# mb9bf566k register map
Vendor: Cypress; Series: mb9bf560l; File version: 1.2
CPU: CM4 r0p1, little endian, MPU, FPU, 4 interrupt priority bits
Registers are 8-bit, read-write, reset 0x0 unless marked. A register's access mark holds for its fields unless they carry their own. Offsets are from the block's base; [hi:lo] are bit positions; {n}, {i} and the like mark numbered series; 'fields as' and 'values as' point back to an identical list.

## GPIO — 0
Base 0x4006F000
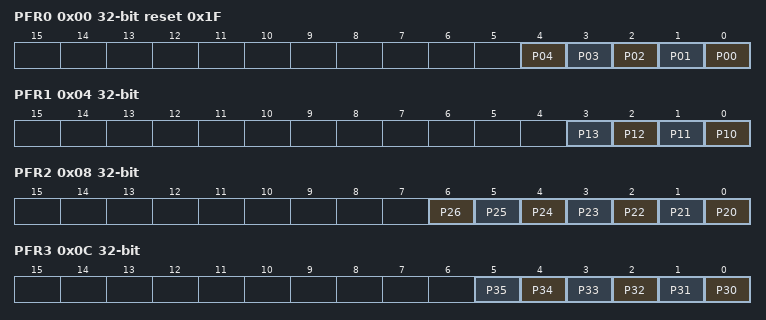
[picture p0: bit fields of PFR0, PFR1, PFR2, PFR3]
0x00 PFR0 32-bit reset 0x1F — Port Function Setting Register 0
  [n] P{n:02} (n=0..4) — Bit{n} of PFR0
0x04 PFR1 32-bit — Port Function Setting Register 1
  [n-10] P{n} (n=10..13) — Bit{n-10} of PFR1
0x08 PFR2 32-bit — Port Function Setting Register 2
  [n-20] P{n} (n=20..26) — Bit{n-20} of PFR2
0x0C PFR3 32-bit — Port Function Setting Register 3
  [n-30] P{n} (n=30..35) — Bit{n-30} of PFR3
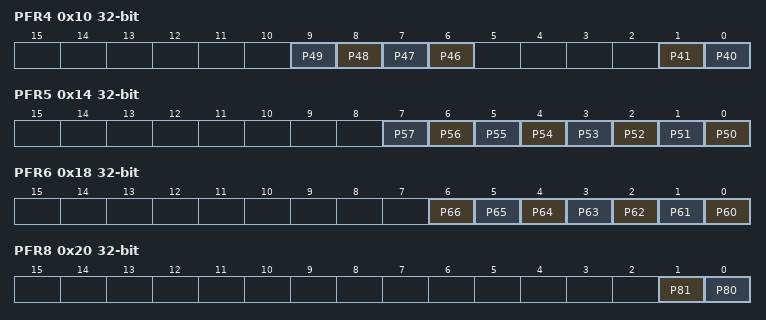
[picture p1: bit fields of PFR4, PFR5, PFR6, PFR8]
0x10 PFR4 32-bit — Port Function Setting Register 4
  [n-40] P{n} (n=46..49) — Bit{n-40} of PFR4
  [1] P41 — Bit1 of PFR4
  [0] P40 — Bit0 of PFR4
0x14 PFR5 32-bit — Port Function Setting Register 5
  [n-50] P{n} (n=50..57) — Bit{n-50} of PFR5
0x18 PFR6 32-bit — Port Function Setting Register 6
  [n-60] P{n} (n=60..66) — Bit{n-60} of PFR6
0x20 PFR8 32-bit — Port Function Setting Register 8
  [1] P81 — Bit1 of PFR8
  [0] P80 — Bit0 of PFR8
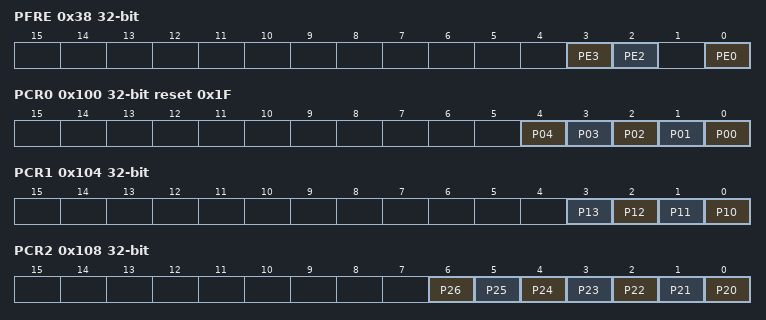
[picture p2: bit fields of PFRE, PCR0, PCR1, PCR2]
0x38 PFRE 32-bit (reset mask 0xB) — Port Function Setting Register E
  [3] PE3 — Bit3 of PFRE
  [2] PE2 — Bit2 of PFRE
  [0] PE0 — Bit0 of PFRE
0x100 PCR0 32-bit reset 0x1F — Pull-up Setting Register 0
  [n] P{n:02} (n=0..4) — Bit{n} of PFR0
0x104 PCR1 32-bit — Pull-up Setting Register 1
  [n-10] P{n} (n=10..13) — Bit{n-10} of PFR1
0x108 PCR2 32-bit — Pull-up Setting Register 2
  [n-20] P{n} (n=20..26) — Bit{n-20} of PFR2
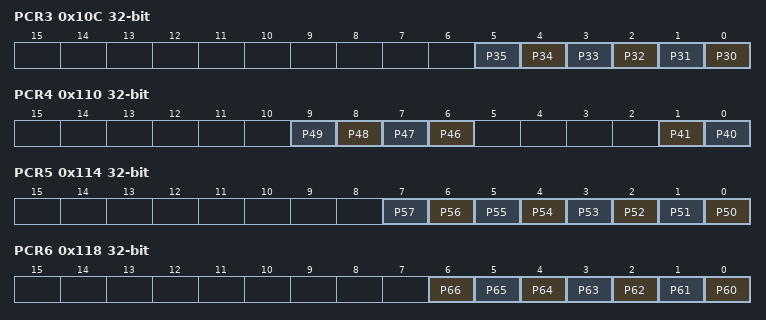
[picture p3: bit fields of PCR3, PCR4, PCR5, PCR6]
0x10C PCR3 32-bit — Pull-up Setting Register 3
  [n-30] P{n} (n=30..35) — Bit{n-30} of PFR3
0x110 PCR4 32-bit — Pull-up Setting Register 4
  fields as PFR4
0x114 PCR5 32-bit — Pull-up Setting Register 5
  [n-50] P{n} (n=50..57) — Bit{n-50} of PFR5
0x118 PCR6 32-bit — Pull-up Setting Register 6
  [n-60] P{n} (n=60..66) — Bit{n-60} of PFR6
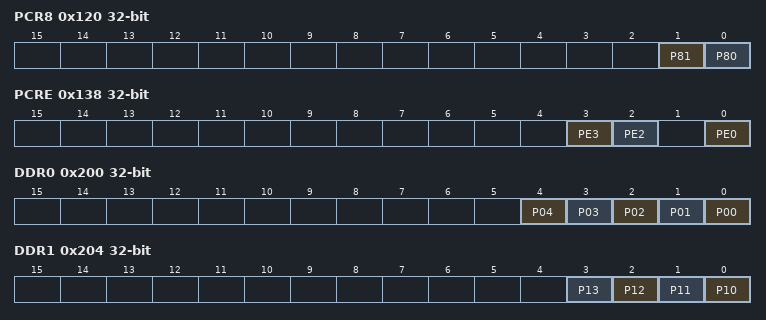
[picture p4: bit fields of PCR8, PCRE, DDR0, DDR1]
0x120 PCR8 32-bit — Pull-up Setting Register 8
  [1] P81 — Bit1 of PFR8
  [0] P80 — Bit0 of PFR8
0x138 PCRE 32-bit (reset mask 0xB) — Pull-up Setting Register E
  fields as PFRE
0x200 DDR0 32-bit — Port input/output Direction Setting Register 0
  [n] P{n:02} (n=0..4) — Bit{n} of DDR0
0x204 DDR1 32-bit — Port input/output Direction Setting Register 1
  [n-10] P{n} (n=10..13) — Bit{n-10} of PFR1
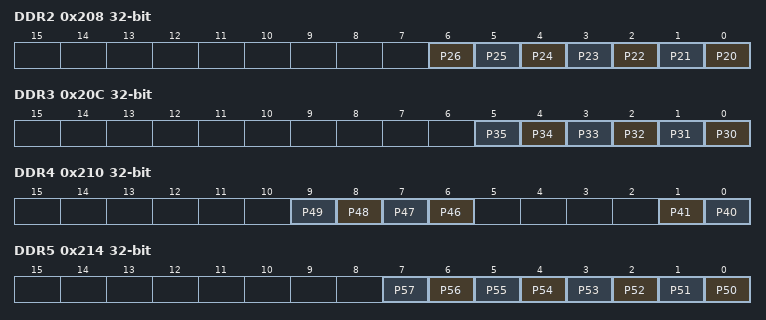
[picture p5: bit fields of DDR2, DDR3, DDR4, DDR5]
0x208 DDR2 32-bit — Port input/output Direction Setting Register 2
  [n-20] P{n} (n=20..26) — Bit{n-20} of PFR2
0x20C DDR3 32-bit — Port input/output Direction Setting Register 3
  [n-30] P{n} (n=30..35) — Bit{n-30} of PFR3
0x210 DDR4 32-bit — Port input/output Direction Setting Register 4
  fields as PFR4
0x214 DDR5 32-bit — Port input/output Direction Setting Register 5
  [n-50] P{n} (n=50..57) — Bit{n-50} of PFR5
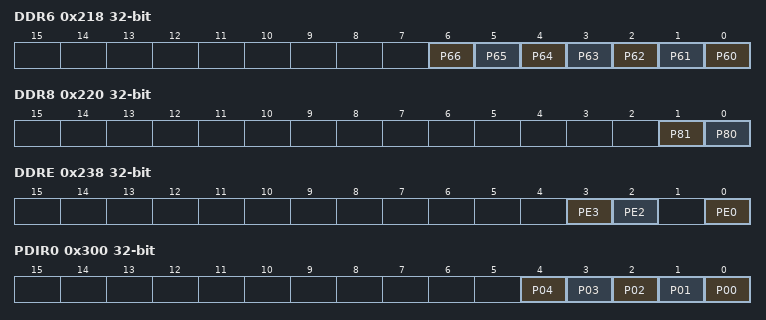
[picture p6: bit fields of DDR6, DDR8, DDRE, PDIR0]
0x218 DDR6 32-bit — Port input/output Direction Setting Register 6
  [n-60] P{n} (n=60..66) — Bit{n-60} of PFR6
0x220 DDR8 32-bit — Port input/output Direction Setting Register 8
  [1] P81 — Bit1 of PFR8
  [0] P80 — Bit0 of PFR8
0x238 DDRE 32-bit (reset mask 0xB) — Port input/output Direction Setting Register E
  fields as PFRE
0x300 PDIR0 32-bit — Port Input Data Register 0
  [n] P{n:02} (n=0..4) — Bit{n} of DDR0
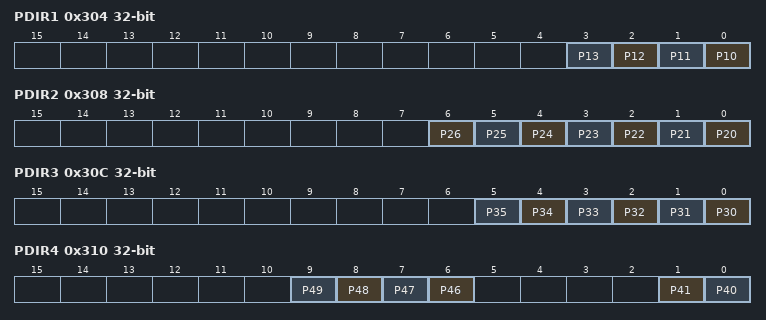
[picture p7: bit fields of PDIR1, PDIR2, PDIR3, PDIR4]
0x304 PDIR1 32-bit — Port Input Data Register 1
  [n-10] P{n} (n=10..13) — Bit{n-10} of PFR1
0x308 PDIR2 32-bit — Port Input Data Register 2
  [n-20] P{n} (n=20..26) — Bit{n-20} of PFR2
0x30C PDIR3 32-bit — Port Input Data Register 3
  [n-30] P{n} (n=30..35) — Bit{n-30} of PFR3
0x310 PDIR4 32-bit — Port Input Data Register 4
  fields as PFR4
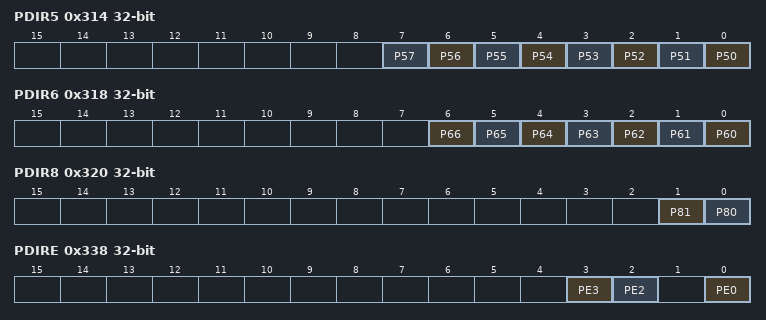
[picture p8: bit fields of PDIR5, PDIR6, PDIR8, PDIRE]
0x314 PDIR5 32-bit — Port Input Data Register 5
  [n-50] P{n} (n=50..57) — Bit{n-50} of PFR5
0x318 PDIR6 32-bit — Port Input Data Register 6
  [n-60] P{n} (n=60..66) — Bit{n-60} of PFR6
0x320 PDIR8 32-bit — Port Input Data Register 8
  [1] P81 — Bit1 of PFR8
  [0] P80 — Bit0 of PFR8
0x338 PDIRE 32-bit (reset mask 0xB) — Port Input Data Register E
  fields as PFRE
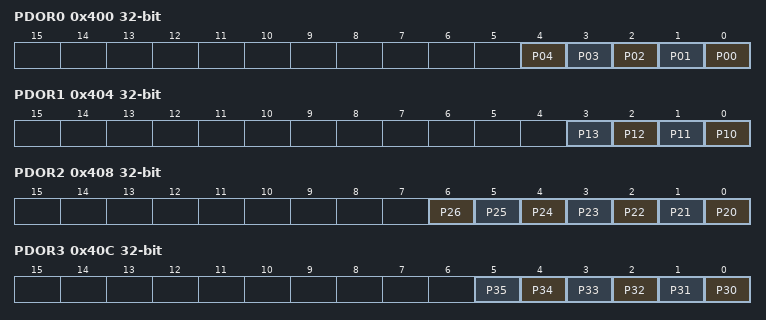
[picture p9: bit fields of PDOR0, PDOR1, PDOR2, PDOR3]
0x400 PDOR0 32-bit — Port Output Data Register 0
  [n] P{n:02} (n=0..4) — Bit{n} of DDR0
0x404 PDOR1 32-bit — Port Output Data Register 1
  [n-10] P{n} (n=10..13) — Bit{n-10} of PFR1
0x408 PDOR2 32-bit — Port Output Data Register 2
  [n-20] P{n} (n=20..26) — Bit{n-20} of PFR2
0x40C PDOR3 32-bit — Port Output Data Register 3
  [n-30] P{n} (n=30..35) — Bit{n-30} of PFR3
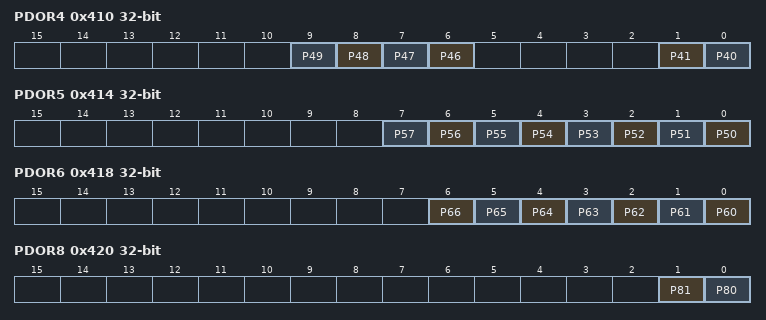
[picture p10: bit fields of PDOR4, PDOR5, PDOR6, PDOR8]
0x410 PDOR4 32-bit — Port Output Data Register 4
  fields as PFR4
0x414 PDOR5 32-bit — Port Output Data Register 5
  [n-50] P{n} (n=50..57) — Bit{n-50} of PFR5
0x418 PDOR6 32-bit — Port Output Data Register 6
  [n-60] P{n} (n=60..66) — Bit{n-60} of PFR6
0x420 PDOR8 32-bit — Port Output Data Register 8
  [1] P81 — Bit1 of PFR8
  [0] P80 — Bit0 of PFR8
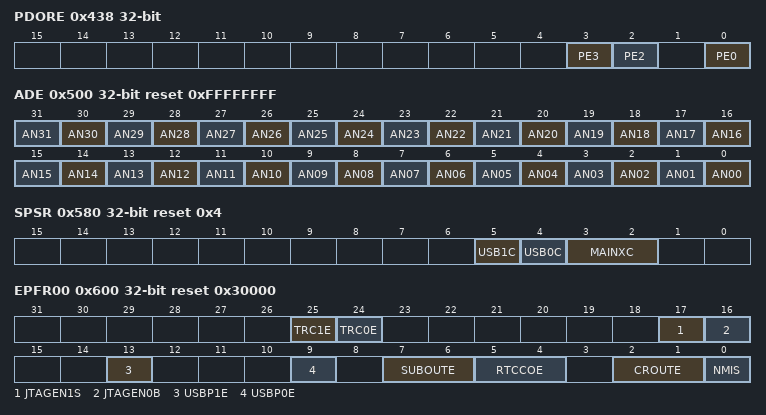
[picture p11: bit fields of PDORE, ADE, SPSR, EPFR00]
0x438 PDORE 32-bit (reset mask 0xB) — Port Output Data Register E
  fields as PFRE
0x500 ADE 32-bit reset 0xFFFFFFFF — Analog Input Setting Register
  [n] AN{n:02} (n=0..31) — Bit{n} of ADE
0x580 SPSR 32-bit reset 0x4 — Special Port Setting Register
  [5] USB1C — USB (ch.1) Pin Setting bit
  [4] USB0C — USB (ch.0) Pin Setting bit
  [3:2] MAINXC — Main Clock (Oscillation) Pin Setting bits
0x600 EPFR00 32-bit reset 0x30000 — Extended Pin Function Setting Register 00
  [25] TRC1E — TRACED Function Select bit 1
  [24] TRC0E — TRACED Function Select bit 0
  [17] JTAGEN1S — JTAG Function Select bit 1
  [16] JTAGEN0B — JTAG Function Select bit 0
  [13] USBP1E — USB ch.1 Function Select bit 1
  [9] USBP0E — USB ch.0 Function Select bit 1
  [7:6] SUBOUTE — Sub clock divide output function select bit
  [5:4] RTCCOE — RTC clock output select bit
  [2:1] CROUTE — Internal high-speed CR Oscillation Output Function Select bit
  [0] NMIS — NMIX Function Select bit
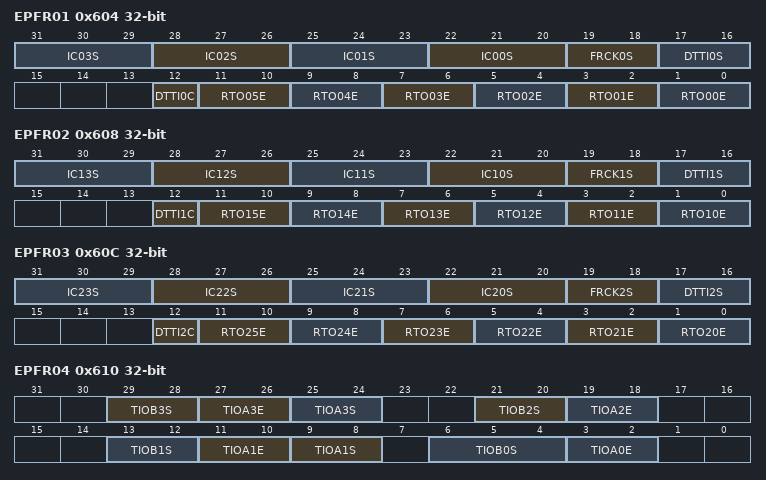
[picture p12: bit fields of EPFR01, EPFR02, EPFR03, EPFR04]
0x604 EPFR01 32-bit — Extended Pin Function Setting Register 01
  [3n+22:3n+20] IC{n:02}S (n=0..3) — IC{n:02} Input Select bits
  [19:18] FRCK0S — FRCK0 Input Select bits
  [17:16] DTTI0S — DTTIX0 Input Select bits
  [12] DTTI0C — DTTIX0 Function Select bit
  [2n+1:2n] RTO{n:02}E (n=0..5) — RTO{n:02} Output Select bits
0x608 EPFR02 32-bit — Extended Pin Function Setting Register 02
  [3n-8:3n-10] IC{n}S (n=10..13) — IC13 Input Select bits
  [19:18] FRCK1S — FRCK1 Input Select bits
  [17:16] DTTI1S — DTTIX1 Input Select bits
  [12] DTTI1C — DTTIX1 Function Select bit
  [2n-19:2n-20] RTO{n}E (n=10..15) — RTO{n} Output Select bits
0x60C EPFR03 32-bit — Extended Pin Function Setting Register 03
  [3n-38:3n-40] IC{n}S (n=20..23) — IC23 Input Select bits
  [19:18] FRCK2S — FRCK2 Input Select bits
  [17:16] DTTI2S — DTTIX2 Input Select bits
  [12] DTTI2C — DTTIX2 Function Select bit
  [2n-39:2n-40] RTO{n}E (n=20..25) — RTO{n} Output Select bits
0x610 EPFR04 32-bit — Extended Pin Function Setting Register 04
  [29:28] TIOB3S — TIOB3 Input Select bits
  [8n+3:8n+2] TIOA{n}E (n=0..3) — TIOA{n} Output Select bits
  [25:24] TIOA3S — TIOA3 Input Select bits
  [21:20] TIOB2S — TIOB2 Input Select bits
  [13:12] TIOB1S — TIOB1 Input Select bits
  [9:8] TIOA1S — TIOA1 Input Select bits
  [6:4] TIOB0S — TIOB0 Input Select bits
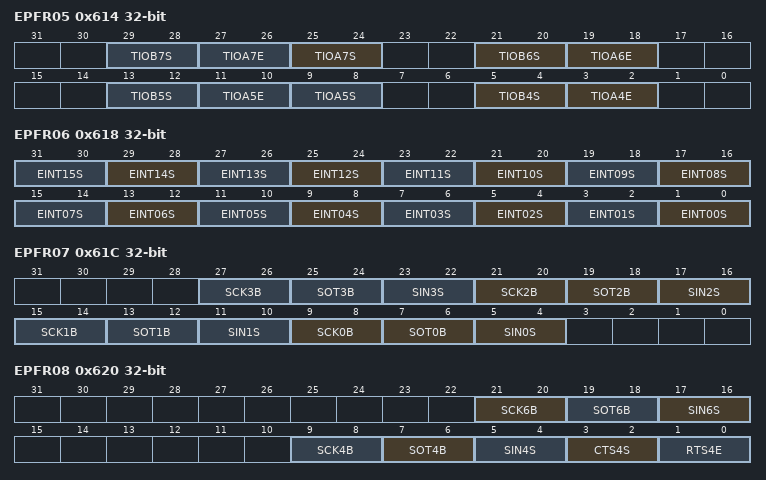
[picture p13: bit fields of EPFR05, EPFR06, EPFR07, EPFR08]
0x614 EPFR05 32-bit — Extended Pin Function Setting Register 05
  [8n-27:8n-28] TIOB{n}S (n=4..7) — TIOB{n} Input Select bits
  [8n-29:8n-30] TIOA{n}E (n=4..7) — TIOA{n} Output Select bits
  [25:24] TIOA7S — TIOA7 Input Select bits
  [9:8] TIOA5S — TIOA5 Input Select bits
0x618 EPFR06 32-bit — Extended Pin Function Setting Register 06
  [2n+1:2n] EINT{n:02}S (n=0..15) — External Interrupt {n:02} Input Select bits
0x61C EPFR07 32-bit — Extended Pin Function Setting Register 07
  [6n+9:6n+8] SCK{n}B (n=0..3) — SCK{n} Input/Output Select bits
  [6n+7:6n+6] SOT{n}B (n=0..3) — SOT{n} Input/Output Select bits
  [6n+5:6n+4] SIN{n}S (n=0..3) — SIN{n} Input Select bits
0x620 EPFR08 32-bit — Extended Pin Function Setting Register 08
  [21:20] SCK6B — SCK6 Input/Output Select bits
  [19:18] SOT6B — SOT6 Input/Output Select bits
  [17:16] SIN6S — SIN6 Input Select bits
  [9:8] SCK4B — SCK4 Input/Output Select bits
  [7:6] SOT4B — SOT4 Input/Output Select bits
  [5:4] SIN4S — SIN4 Input Select bits
  [3:2] CTS4S — CTS4 Input/Output Select bits
  [1:0] RTS4E — RTS4 Input/Output Select bits
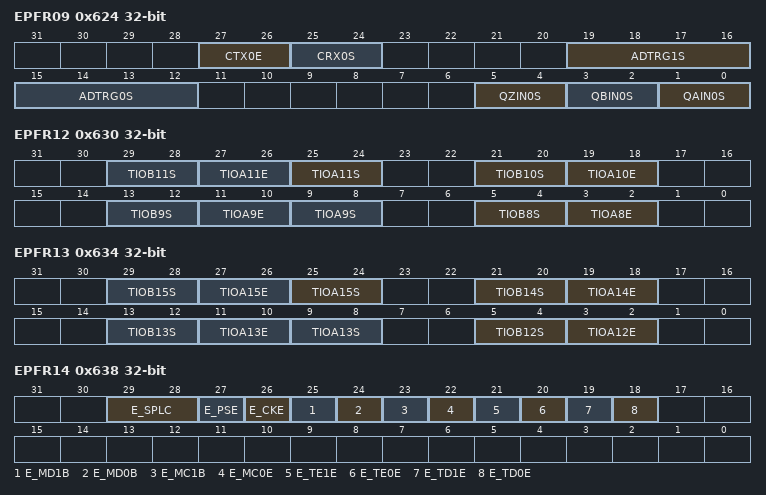
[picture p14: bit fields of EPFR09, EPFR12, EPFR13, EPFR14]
0x624 EPFR09 32-bit — Extended Pin Function Setting Register 09
  [27:26] CTX0E — CTX0E Output Select bits
  [25:24] CRX0S — CRX0S Input Select bits
  [19:16] ADTRG1S — ADTRG1 Input Select bits
  [15:12] ADTRG0S — ADTRG0 Input Select bits
  [5:4] QZIN0S — QZIN0S Input Select bits
  [3:2] QBIN0S — QBIN0S Input Select bits
  [1:0] QAIN0S — QAIN0S Input Select bits$
0x628 EPFR10 32-bit reset not defined — Extended Pin Function Setting Register 10
0x62C EPFR11 32-bit (reset mask 0x3FFFFFF) — Extended Pin Function Setting Register 11
0x630 EPFR12 32-bit — Extended Pin Function Setting Register 12
  [8n-59:8n-60] TIOB{n}S (n=8..11) — TIOB{n} Input Select bits
  [8n-61:8n-62] TIOA{n}E (n=8..11) — TIOA{n} Output Select bits
  [25:24] TIOA11S — TIOA11 Input Select bits
  [9:8] TIOA9S — TIOA9 Input Select bits
0x634 EPFR13 32-bit — Extended Pin Function Setting Register 13
  [8n-91:8n-92] TIOB{n}S (n=12..15) — TIOB{n} Input Select bits
  [8n-93:8n-94] TIOA{n}E (n=12..15) — TIOA{n} Output Select bits
  [25:24] TIOA15S — TIOA15 Input Select bits
  [9:8] TIOA13S — TIOA13 Input Select bits
0x638 EPFR14 32-bit — Extended Pin Function Setting Register 14
  [29:28] E_SPLC — Input cutoff Select bit in Standby of input Pin for Ethernet-MAC
  [27] E_PSE — PPS0_PPS1 Output Select bit for Ethernet-MAC
  [26] E_CKE — E_COUT Output Select bit
  [25] E_MD1B — E_MDO1 I/O Select bit
  [24] E_MD0B — E_MDO0 I/O Select bit
  [23] E_MC1B — E_MDC1 I/O Select bit
  [22] E_MC0E — E_MDC0 Output Select bit
  [21] E_TE1E — E_TXER0_TXEN1 Output Select bit
  [20] E_TE0E — E_TXEN0 Output Select bit
  [19] E_TD1E — E_TX02_TX10, E_TX03_TX11 Output Select bit
  [18] E_TD0E — E_TX00, E_TX01 Output Select bit
0x63C EPFR15 32-bit — Extended Pin Function Setting Register 15
  [2n-31:2n-32] EINT{n}S (n=16..31) — External Interrupt {n} Input Select bits
0x640 EPFR16 32-bit — Extended Pin Function Setting Register 16
  [29] SFMPBC — MFS ch.B I2C FastMode+ Select bit
  [28] SFMPAC — MFS ch.A I2C FastMode+ Select bit
{0x600+4i} EPFR{i} 32-bit reset not defined (i=17..20) — Extended Pin Function Setting Register {i}
0x700 PZR0 32-bit — Port Pseudo Open Drain Setting Register 0
  [n] P{n:02} (n=0..4) — Bit{n} of DDR0
0x704 PZR1 32-bit — Port Pseudo Open Drain Setting Register 1
  [n-10] P{n} (n=10..13) — Bit{n-10} of PFR1
0x708 PZR2 32-bit — Port Pseudo Open Drain Setting Register 2
  [n-20] P{n} (n=20..26) — Bit{n-20} of PFR2
0x70C PZR3 32-bit — Port Pseudo Open Drain Setting Register 3
  [n-30] P{n} (n=30..35) — Bit{n-30} of PFR3
0x710 PZR4 32-bit — Port Pseudo Open Drain Setting Register 4
  fields as PFR4
0x714 PZR5 32-bit — Port Pseudo Open Drain Setting Register 5
  [n-50] P{n} (n=50..57) — Bit{n-50} of PFR5
0x718 PZR6 32-bit — Port Pseudo Open Drain Setting Register 6
  [n-60] P{n} (n=60..66) — Bit{n-60} of PFR6
0x720 PZR8 32-bit — Port Pseudo Open Drain Setting Register 8
  [1] P81 — Bit1 of PFR8
  [0] P80 — Bit0 of PFR8
0x738 PZRE 32-bit (reset mask 0xB) — Port Pseudo Open Drain Setting Register E
  fields as PFRE
